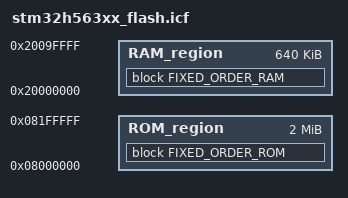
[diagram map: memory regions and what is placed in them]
/*###ICF### Section handled by ICF editor, don't touch! ****/
/*-Editor annotation file-*/
/* IcfEditorFile="$TOOLKIT_DIR$\config\ide\IcfEditor\cortex_v1_0.xml" */
/*-Specials-*/
define symbol __ICFEDIT_intvec_start__ = 0x08000000;
/*-Memory Regions-*/
define symbol __ICFEDIT_region_ROM_start__     = 0x08000000;
define symbol __ICFEDIT_region_ROM_end__       = 0x081FFFFF;
define symbol __ICFEDIT_region_RAM_start__     = 0x20000000;
define symbol __ICFEDIT_region_RAM_end__       = 0x2009FFFF;

/*-Sizes-*/
define symbol __ICFEDIT_size_cstack__ = 0x400;
define symbol __ICFEDIT_size_heap__   = 0x200;
/**** End of ICF editor section. ###ICF###*/


define memory mem with size = 4G;
define region ROM_region      = mem:[from __ICFEDIT_region_ROM_start__   to __ICFEDIT_region_ROM_end__];
define region RAM_region      = mem:[from __ICFEDIT_region_RAM_start__   to __ICFEDIT_region_RAM_end__];

define block CSTACK    with alignment = 8, size = __ICFEDIT_size_cstack__   { };
define block HEAP      with alignment = 8, size = __ICFEDIT_size_heap__     { };

initialize by copy { readwrite };
do not initialize  { section .noinit };

define block EMPTY_PADDING with alignment = 4 { };
define block FIXED_ORDER_ROM with fixed order { readonly section .intvec, readonly, block EMPTY_PADDING};
keep {block EMPTY_PADDING };
place in ROM_region { block FIXED_ORDER_ROM };

define block FIXED_ORDER_RAM with fixed order { section backup_buffer_section, readwrite, block CSTACK, block HEAP};
place in RAM_region   { block FIXED_ORDER_RAM };
